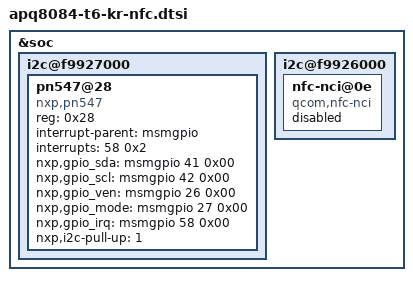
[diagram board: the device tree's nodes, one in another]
/* Copyright (c) 2012, Code Aurora Forum. All rights reserved.
 *
 * This program is free software; you can redistribute it and/or modify
 * it under the terms of the GNU General Public License version 2 and
 * only version 2 as published by the Free Software Foundation.
 *
 * This program is distributed in the hope that it will be useful,
 * but WITHOUT ANY WARRANTY; without even the implied warranty of
 * MERCHANTABILITY or FITNESS FOR A PARTICULAR PURPOSE.  See the
 * GNU General Public License for more details.
 */

&soc {
	i2c@f9927000 {
		pn547@28 {
			compatible = "nxp,pn547";
			status = "ok";
			reg = <0x28>;
			interrupt-parent = <&msmgpio>;
			interrupts = <58 0x2>;
			nxp,gpio_sda = <&msmgpio 41 0x00>;
			nxp,gpio_scl = <&msmgpio 42 0x00>;
			nxp,gpio_ven = <&msmgpio 26 0x00>;
			nxp,gpio_mode = <&msmgpio 27 0x00>;
			nxp,gpio_irq = <&msmgpio 58 0x00>;
			nxp,i2c-pull-up = <1>;
		};
	};

	i2c@f9926000 {
		nfc-nci@0e {
			compatible = "qcom,nfc-nci";
			status = "disable";
		};
	};
};
